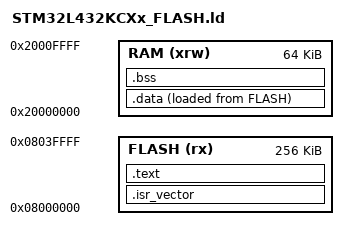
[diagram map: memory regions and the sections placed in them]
ENTRY(Reset_Handler)

MEMORY
{
  RAM    (xrw) : ORIGIN = 0x20000000, LENGTH = 64K
  FLASH  (rx)  : ORIGIN = 0x08000000, LENGTH = 256K
}

/* Ensure 8-byte stack alignment for ARM AAPCS compliance */
_estack = ALIGN(ORIGIN(RAM) + LENGTH(RAM), 8);

SECTIONS
{
  .isr_vector :
  {
    . = ALIGN(4);
    KEEP(*(.isr_vector))
    . = ALIGN(4);
  } >FLASH

  .text :
  {
    . = ALIGN(4);
    *(.text)
    *(.text*)
    *(.rodata)
    *(.rodata*)
    . = ALIGN(4);
    _etext = .;
  } >FLASH

  _sidata = LOADADDR(.data);

  .data :
  {
    . = ALIGN(4);
    _sdata = .;
    *(.data)
    *(.data*)
    . = ALIGN(4);
    _edata = .;
  } >RAM AT> FLASH

  .bss :
  {
    . = ALIGN(4);
    _sbss = .;
    *(.bss)
    *(.bss*)
    *(COMMON)
    . = ALIGN(4);
    _ebss = .;
  } >RAM

  _end = .;
}
